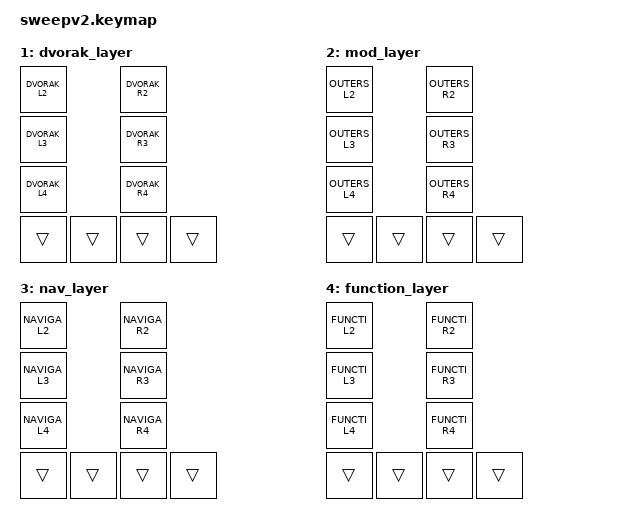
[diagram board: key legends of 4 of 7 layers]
/*
 * Copyright (c) 2020 The ZMK Contributors
 *
 * SPDX-License-Identifier: MIT
 */

#include <behaviors.dtsi>
#include <dt-bindings/zmk/keys.h>
#include <dt-bindings/zmk/bt.h>
#include <dt-bindings/zmk/outputs.h>
#include "include/definitions.c"

/ {
        #include "behaviors/combos.dtsi"
        keymap {
                compatible = "zmk,keymap";
                qwerty_layer {
                        bindings = <
                                QWERTY_L2         QWERTY_R2
                                QWERTY_L3         QWERTY_R3
                                QWERTY_L4         QWERTY_R4
                                THUMBS_2L         THUMBS_2R
                        >;
                };
                dvorak_layer {
                        bindings = <
                                DVORAK_L2         DVORAK_R2
                                DVORAK_L3         DVORAK_R3
                                DVORAK_L4         DVORAK_R4
                                &trans &trans     &trans &trans
                        >;
                };
                mod_layer {
                        bindings = <
                                OUTERS_L2         OUTERS_R2
                                OUTERS_L3         OUTERS_R3
                                OUTERS_L4         OUTERS_R4
                                &trans &trans     &trans &trans
                        >;
                };
                nav_layer {
                        bindings = <
                                NAVIGA_L2         NAVIGA_R2
                                NAVIGA_L3         NAVIGA_R3
                                NAVIGA_L4         NAVIGA_R4
                                &trans &trans     &trans &trans
                        >;
                };
                function_layer {
                        bindings = <
                                FUNCTI_L2         FUNCTI_R2
                                FUNCTI_L3         FUNCTI_R3
                                FUNCTI_L4         FUNCTI_R4
                                &trans &trans     &trans &trans
                        >;
                };

                number_layer {
                        bindings = <
                                NUMBER_L2         NUMBER_R2
                                NUMBER_L3         NUMBER_R3
                                NUMBER_L4         NUMBER_R4
                                THUMBS_2N         &trans &trans
                        >;
                };
                symbol_layer {
                        bindings = <
                                SYMBOL_L2         SYMBOL_R2
                                SYMBOL_L3         SYMBOL_R3
                                SYMBOL_L4         SYMBOL_R4
                                THUMBS_2S         &trans &trans
                        >;
                };
        };
};

// vim: filetype=dts

